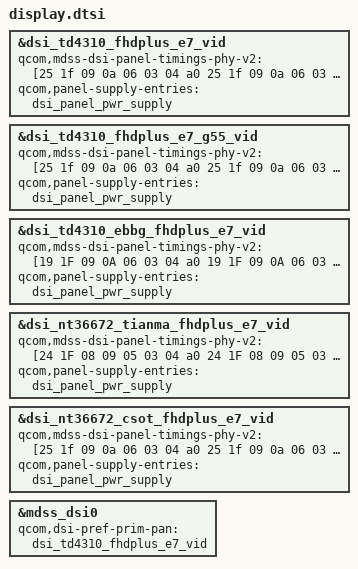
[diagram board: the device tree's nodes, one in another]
#include "../common/panel/dsi-panel-td4310-fhdplus-video_e7.dtsi"
#include "../common/panel/dsi-panel-td4310-fhdplus-video_e7_g55.dtsi"
#include "../common/panel/dsi-panel-td4310-ebbg-fhdplus-video_e7.dtsi"
#include "../common/panel/dsi-panel-nt36672-tianma-fhdplus-video_e7.dtsi"
#include "../common/panel/dsi-panel-nt36672-csot-fhdplus-video_e7.dtsi"

&dsi_td4310_fhdplus_e7_vid {
	qcom,mdss-dsi-panel-timings-phy-v2 = [25 1f 09 0a 06 03 04 a0
					      25 1f 09 0a 06 03 04 a0
					      25 1f 09 0a 06 03 04 a0
					      25 1f 09 0a 06 03 04 a0
					      25 1f 08 0a 06 03 04 a0];
};

&dsi_td4310_fhdplus_e7_g55_vid {
	qcom,mdss-dsi-panel-timings-phy-v2 = [25 1f 09 0a 06 03 04 a0
					      25 1f 09 0a 06 03 04 a0
					      25 1f 09 0a 06 03 04 a0
					      25 1f 09 0a 06 03 04 a0
					      25 1f 08 0a 06 03 04 a0];
};

&dsi_td4310_ebbg_fhdplus_e7_vid {
	qcom,mdss-dsi-panel-timings-phy-v2 = [19 1F 09 0A 06 03 04 a0
		19 1F 09 0A 06 03 04 a0
		19 1F 09 0A 06 03 04 a0
		19 1F 09 0A 06 03 04 a0
		19 1E 08 0A 06 03 04 a0];
};

&dsi_nt36672_tianma_fhdplus_e7_vid {
	qcom,mdss-dsi-panel-timings-phy-v2 = [24 1F 08 09 05 03 04 a0
		24 1F 08 09 05 03 04 a0
		24 1F 08 09 05 03 04 a0
		24 1F 08 09 05 03 04 a0
		24 1C 08 09 05 03 04 a0];
};

&dsi_nt36672_csot_fhdplus_e7_vid {
	qcom,mdss-dsi-panel-timings-phy-v2 = [25 1f 09 0a 06 03 04 a0
		25 1f 09 0a 06 03 04 a0
		25 1f 09 0a 06 03 04 a0
		25 1f 09 0a 06 03 04 a0
		25 1e 08 0a 06 03 04 a0];
};

&mdss_dsi0 {
	qcom,dsi-pref-prim-pan = <&dsi_td4310_fhdplus_e7_vid>;
};

&dsi_td4310_fhdplus_e7_vid {
	qcom,panel-supply-entries = <&dsi_panel_pwr_supply>;
};

&dsi_td4310_fhdplus_e7_g55_vid {
	qcom,panel-supply-entries = <&dsi_panel_pwr_supply>;
};


&dsi_td4310_ebbg_fhdplus_e7_vid {
	qcom,panel-supply-entries = <&dsi_panel_pwr_supply>;
};

&dsi_nt36672_tianma_fhdplus_e7_vid {
	qcom,panel-supply-entries = <&dsi_panel_pwr_supply>;
};

&dsi_nt36672_csot_fhdplus_e7_vid {
	qcom,panel-supply-entries = <&dsi_panel_pwr_supply>;
};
